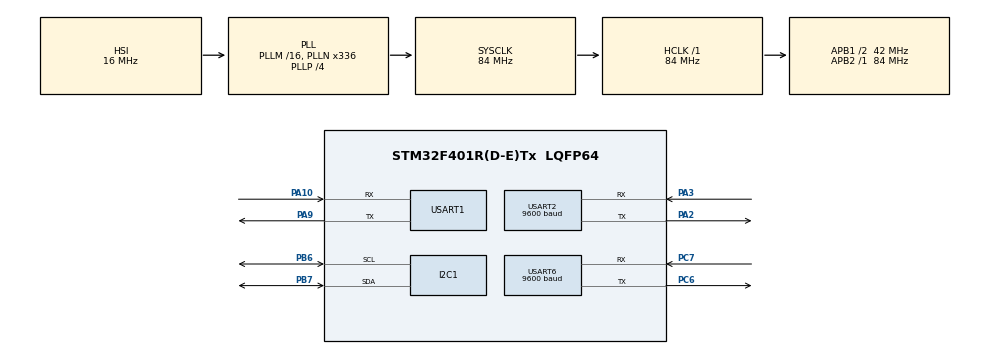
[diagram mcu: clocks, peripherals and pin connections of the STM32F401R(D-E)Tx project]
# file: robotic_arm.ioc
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Dma.Request0=USART6_RX
Dma.USART6_RX.0.Direction=DMA_PERIPH_TO_MEMORY
Dma.USART6_RX.0.FIFOMode=DMA_FIFOMODE_DISABLE
Dma.USART6_RX.0.Instance=DMA2_Stream1
Dma.USART6_RX.0.MemDataAlignment=DMA_MDATAALIGN_BYTE
Dma.USART6_RX.0.MemInc=DMA_MINC_ENABLE
Dma.USART6_RX.0.Mode=DMA_CIRCULAR
Dma.USART6_RX.0.PeriphDataAlignment=DMA_PDATAALIGN_BYTE
Dma.USART6_RX.0.PeriphInc=DMA_PINC_DISABLE
Dma.USART6_RX.0.Priority=DMA_PRIORITY_LOW
Mcu.Family=STM32F4
Mcu.Name=STM32F401R(D-E)Tx
Mcu.Package=LQFP64
NVIC.DMA2_Stream1_IRQn=true\:0\:0\:false\:false\:true\:false\:true\:true
NVIC.I2C1_ER_IRQn=true\:0\:0\:false\:false\:true\:true\:true\:true
NVIC.I2C1_EV_IRQn=true\:0\:0\:false\:false\:true\:true\:true\:true
NVIC.PriorityGroup=NVIC_PRIORITYGROUP_0
NVIC.TIM1_UP_TIM10_IRQn=true\:0\:0\:false\:false\:true\:true\:true\:true
NVIC.USART2_IRQn=true\:0\:0\:false\:false\:true\:true\:true\:true
NVIC.USART6_IRQn=true\:0\:0\:false\:false\:true\:true\:true\:true
PA10.GPIO_ModeDefaultPP=GPIO_MODE_AF_PP
PA10.GPIO_PuPd=GPIO_NOPULL
PA10.Mode=Asynchronous
PA10.Signal=USART1_RX
PA2.Mode=Asynchronous
PA2.Signal=USART2_TX
PA3.Mode=Asynchronous
PA3.Signal=USART2_RX
PA9.GPIO_ModeDefaultPP=GPIO_MODE_AF_PP
PA9.GPIO_PuPd=GPIO_NOPULL
PA9.GPIO_Speed=GPIO_SPEED_FREQ_VERY_HIGH
PA9.Mode=Asynchronous
PA9.Signal=USART1_TX
PB6.GPIO_Mode=GPIO_MODE_AF_OD
PB6.GPIO_Pu=GPIO_PULLUP
PB6.GPIO_Speed=GPIO_SPEED_FREQ_VERY_HIGH
PB6.Mode=I2C
PB6.Signal=I2C1_SCL
PB7.GPIO_Mode=GPIO_MODE_AF_OD
PB7.GPIO_Pu=GPIO_PULLUP
PB7.GPIO_Speed=GPIO_SPEED_FREQ_VERY_HIGH
PB7.Mode=I2C
PB7.Signal=I2C1_SDA
PC6.GPIO_ModeDefaultPP=GPIO_MODE_AF_OD
PC6.Mode=Asynchronous
PC6.Signal=USART6_TX
PC7.GPIO_ModeDefaultPP=GPIO_MODE_AF_OD
PC7.Mode=Asynchronous
PC7.Signal=USART6_RX
ProjectManager.HeapSize=0x200
ProjectManager.StackSize=0x400
ProjectManager.TargetToolchain=STM32CubeIDE
RCC.48MHZClocksFreq_Value=48000000
RCC.AHBFreq_Value=84000000
RCC.APB1CLKDivider=RCC_HCLK_DIV2
RCC.APB1Freq_Value=42000000
RCC.APB1TimFreq_Value=84000000
RCC.APB2Freq_Value=84000000
RCC.APB2TimFreq_Value=84000000
RCC.CortexFreq_Value=84000000
RCC.HCLKFreq_Value=84000000
RCC.HSE_VALUE=8000000
RCC.HSI_VALUE=16000000
RCC.LSE_VALUE=32768
RCC.PLLN=336
RCC.PLLP=RCC_PLLP_DIV4
RCC.PLLQ=7
RCC.SYSCLKFreq_VALUE=84000000
RCC.SYSCLKSource=RCC_SYSCLKSOURCE_PLLCLK
RCC.VCOOutputFreq_Value=336000000
TIM10.Period=3999
TIM10.Prescaler=19999
USART1.VirtualMode=VM_ASYNC
USART2.BaudRate=9600
USART2.VirtualMode=VM_ASYNC
USART6.BaudRate=9600
USART6.VirtualMode=VM_ASYNC
VP_TIM10_VS_ClockSourceINT.Mode=Enable_Timer
board=NUCLEO-F401RE

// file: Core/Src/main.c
/* USER CODE BEGIN Header */
/**
  ******************************************************************************
  * @file           : main.c
  * @brief          : Main program body
  ******************************************************************************
  * @attention
  *
  * Copyright (c) 2023 STMicroelectronics.
  * All rights reserved.
  *
  * This software is licensed under terms that can be found in the LICENSE file
  * in the root directory of this software component.
  * If no LICENSE file comes with this software, it is provided AS-IS.
  *
  ******************************************************************************
  */
/* USER CODE END Header */
#include "main.h"

I2C_HandleTypeDef hi2c1;

TIM_HandleTypeDef htim10;

UART_HandleTypeDef huart1;
UART_HandleTypeDef huart2;
UART_HandleTypeDef huart6;
DMA_HandleTypeDef hdma_usart6_rx;

/* USER CODE BEGIN PV */
union xbee_buff_t xbee_buff;
/* USER CODE END PV */

void SystemClock_Config(void);
static void MX_GPIO_Init(void);
static void MX_DMA_Init(void);
static void MX_USART1_UART_Init(void);
static void MX_USART2_UART_Init(void);
static void MX_USART6_UART_Init(void);
static void MX_I2C1_Init(void);
static void MX_TIM10_Init(void);

/* USER CODE BEGIN 0 */
void HAL_UART_RxCpltCallback(UART_HandleTypeDef *huart){

		HAL_UART_Receive_DMA(&huart6, xbee_buff.xbee_buf_8, 12);
}

/* USER CODE END 0 */

int main(void)
{

  /* MCU Configuration--------------------------------------------------------*/

  /* Reset of all peripherals, Initializes the Flash interface and the Systick. */
  HAL_Init();

  /* Configure the system clock */
  SystemClock_Config();

  /* Initialize all configured peripherals */
  MX_GPIO_Init();
  MX_DMA_Init();
  MX_USART1_UART_Init();
  MX_USART2_UART_Init();
  MX_USART6_UART_Init();
  MX_I2C1_Init();
  MX_TIM10_Init();
  /* USER CODE BEGIN 2 */
  init();
  /* USER CODE END 2 */

  /* Infinite loop */
  while (1)
  {

    /* USER CODE BEGIN 3 */
	  loop();
  }
  /* USER CODE END 3 */
}

void SystemClock_Config(void)
{
  RCC_OscInitTypeDef RCC_OscInitStruct = {0};
  RCC_ClkInitTypeDef RCC_ClkInitStruct = {0};

  /** Configure the main internal regulator output voltage
  */
  __HAL_RCC_PWR_CLK_ENABLE();
  __HAL_PWR_VOLTAGESCALING_CONFIG(PWR_REGULATOR_VOLTAGE_SCALE2);

  /** Initializes the RCC Oscillators according to the specified parameters
  * in the RCC_OscInitTypeDef structure.
  */
  RCC_OscInitStruct.OscillatorType = RCC_OSCILLATORTYPE_HSI;
  RCC_OscInitStruct.HSIState = RCC_HSI_ON;
  RCC_OscInitStruct.HSICalibrationValue = RCC_HSICALIBRATION_DEFAULT;
  RCC_OscInitStruct.PLL.PLLState = RCC_PLL_ON;
  RCC_OscInitStruct.PLL.PLLSource = RCC_PLLSOURCE_HSI;
  RCC_OscInitStruct.PLL.PLLM = 16;
  RCC_OscInitStruct.PLL.PLLN = 336;
  RCC_OscInitStruct.PLL.PLLP = RCC_PLLP_DIV4;
  RCC_OscInitStruct.PLL.PLLQ = 7;
  if (HAL_RCC_OscConfig(&RCC_OscInitStruct) != HAL_OK)
  {
    Error_Handler();
  }

  /** Initializes the CPU, AHB and APB buses clocks
  */
  RCC_ClkInitStruct.ClockType = RCC_CLOCKTYPE_HCLK|RCC_CLOCKTYPE_SYSCLK
                              |RCC_CLOCKTYPE_PCLK1|RCC_CLOCKTYPE_PCLK2;
  RCC_ClkInitStruct.SYSCLKSource = RCC_SYSCLKSOURCE_PLLCLK;
  RCC_ClkInitStruct.AHBCLKDivider = RCC_SYSCLK_DIV1;
  RCC_ClkInitStruct.APB1CLKDivider = RCC_HCLK_DIV2;
  RCC_ClkInitStruct.APB2CLKDivider = RCC_HCLK_DIV1;

  if (HAL_RCC_ClockConfig(&RCC_ClkInitStruct, FLASH_LATENCY_2) != HAL_OK)
  {
    Error_Handler();
  }
}

static void MX_I2C1_Init(void)
{

  hi2c1.Instance = I2C1;
  hi2c1.Init.ClockSpeed = 100000;
  hi2c1.Init.DutyCycle = I2C_DUTYCYCLE_2;
  hi2c1.Init.OwnAddress1 = 0;
  hi2c1.Init.AddressingMode = I2C_ADDRESSINGMODE_7BIT;
  hi2c1.Init.DualAddressMode = I2C_DUALADDRESS_DISABLE;
  hi2c1.Init.OwnAddress2 = 0;
  hi2c1.Init.GeneralCallMode = I2C_GENERALCALL_DISABLE;
  hi2c1.Init.NoStretchMode = I2C_NOSTRETCH_DISABLE;
  if (HAL_I2C_Init(&hi2c1) != HAL_OK)
  {
    Error_Handler();
  }

}

static void MX_TIM10_Init(void)
{

  htim10.Instance = TIM10;
  htim10.Init.Prescaler = 19999;
  htim10.Init.CounterMode = TIM_COUNTERMODE_UP;
  htim10.Init.Period = 3999;
  htim10.Init.ClockDivision = TIM_CLOCKDIVISION_DIV1;
  htim10.Init.AutoReloadPreload = TIM_AUTORELOAD_PRELOAD_DISABLE;
  if (HAL_TIM_Base_Init(&htim10) != HAL_OK)
  {
    Error_Handler();
  }

}

static void MX_USART1_UART_Init(void)
{

  huart1.Instance = USART1;
  huart1.Init.BaudRate = 115200;
  huart1.Init.WordLength = UART_WORDLENGTH_8B;
  huart1.Init.StopBits = UART_STOPBITS_1;
  huart1.Init.Parity = UART_PARITY_NONE;
  huart1.Init.Mode = UART_MODE_TX_RX;
  huart1.Init.HwFlowCtl = UART_HWCONTROL_NONE;
  huart1.Init.OverSampling = UART_OVERSAMPLING_16;
  if (HAL_UART_Init(&huart1) != HAL_OK)
  {
    Error_Handler();
  }

}

static void MX_USART2_UART_Init(void)
{

  huart2.Instance = USART2;
  huart2.Init.BaudRate = 9600;
  huart2.Init.WordLength = UART_WORDLENGTH_8B;
  huart2.Init.StopBits = UART_STOPBITS_1;
  huart2.Init.Parity = UART_PARITY_NONE;
  huart2.Init.Mode = UART_MODE_TX_RX;
  huart2.Init.HwFlowCtl = UART_HWCONTROL_NONE;
  huart2.Init.OverSampling = UART_OVERSAMPLING_16;
  if (HAL_UART_Init(&huart2) != HAL_OK)
  {
    Error_Handler();
  }

}

static void MX_USART6_UART_Init(void)
{

  huart6.Instance = USART6;
  huart6.Init.BaudRate = 9600;
  huart6.Init.WordLength = UART_WORDLENGTH_8B;
  huart6.Init.StopBits = UART_STOPBITS_1;
  huart6.Init.Parity = UART_PARITY_NONE;
  huart6.Init.Mode = UART_MODE_TX_RX;
  huart6.Init.HwFlowCtl = UART_HWCONTROL_NONE;
  huart6.Init.OverSampling = UART_OVERSAMPLING_16;
  if (HAL_UART_Init(&huart6) != HAL_OK)
  {
    Error_Handler();
  }

}

static void MX_DMA_Init(void)
{

  /* DMA controller clock enable */
  __HAL_RCC_DMA2_CLK_ENABLE();

  /* DMA interrupt init */
  /* DMA2_Stream1_IRQn interrupt configuration */
  HAL_NVIC_SetPriority(DMA2_Stream1_IRQn, 0, 0);
  HAL_NVIC_EnableIRQ(DMA2_Stream1_IRQn);

}

static void MX_GPIO_Init(void)
{

  /* GPIO Ports Clock Enable */
  __HAL_RCC_GPIOA_CLK_ENABLE();
  __HAL_RCC_GPIOC_CLK_ENABLE();
  __HAL_RCC_GPIOB_CLK_ENABLE();

}

void Error_Handler(void)
{
  __disable_irq();
  while (1)
  {
  }
}
